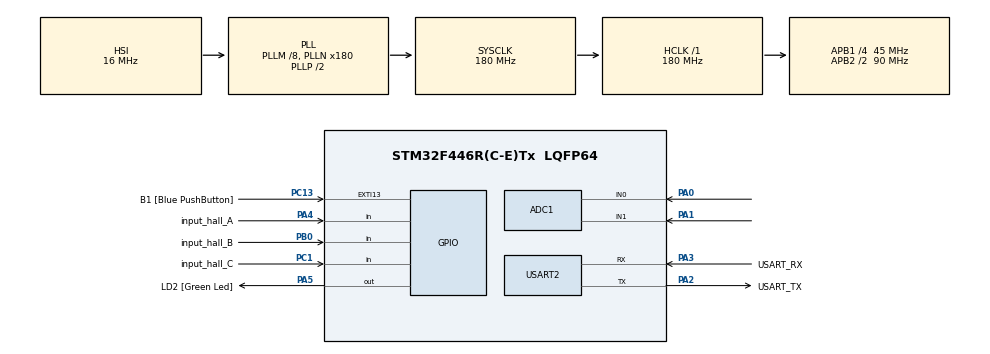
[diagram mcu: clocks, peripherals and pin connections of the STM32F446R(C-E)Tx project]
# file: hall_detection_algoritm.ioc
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ADC1.Channel-0\#ChannelRegularConversion=ADC_CHANNEL_0
ADC1.Channel-1\#ChannelRegularConversion=ADC_CHANNEL_1
ADC1.ContinuousConvMode=ENABLE
ADC1.DMAContinuousRequests=ENABLE
ADC1.EOCSelection=ADC_EOC_SEQ_CONV
ADC1.ExternalTrigConv=ADC_EXTERNALTRIGCONV_T8_TRGO
ADC1.InjNumberOfConversion=0
ADC1.NbrOfConversion=2
ADC1.NbrOfConversionFlag=1
ADC1.Rank-0\#ChannelRegularConversion=1
ADC1.Rank-1\#ChannelRegularConversion=2
ADC1.SamplingTime-0\#ChannelRegularConversion=ADC_SAMPLETIME_15CYCLES
ADC1.SamplingTime-1\#ChannelRegularConversion=ADC_SAMPLETIME_15CYCLES
ADC1.master=1
Dma.ADC1.0.Direction=DMA_PERIPH_TO_MEMORY
Dma.ADC1.0.FIFOMode=DMA_FIFOMODE_DISABLE
Dma.ADC1.0.Instance=DMA2_Stream0
Dma.ADC1.0.MemDataAlignment=DMA_MDATAALIGN_WORD
Dma.ADC1.0.MemInc=DMA_MINC_ENABLE
Dma.ADC1.0.Mode=DMA_CIRCULAR
Dma.ADC1.0.PeriphDataAlignment=DMA_PDATAALIGN_WORD
Dma.ADC1.0.PeriphInc=DMA_PINC_DISABLE
Dma.ADC1.0.Priority=DMA_PRIORITY_LOW
Dma.Request0=ADC1
Mcu.Family=STM32F4
Mcu.Name=STM32F446R(C-E)Tx
Mcu.Package=LQFP64
NVIC.DMA2_Stream0_IRQn=true\:0\:0\:false\:false\:true\:false\:true\:true
NVIC.PriorityGroup=NVIC_PRIORITYGROUP_0
NVIC.TIM8_UP_TIM13_IRQn=true\:0\:0\:false\:false\:true\:true\:true\:true
PA0-WKUP.Signal=ADCx_IN0
PA1.Signal=ADCx_IN1
PA13.GPIO_Label=TMS
PA13.Mode=Serial_Wire
PA13.Signal=SYS_JTMS-SWDIO
PA14.GPIO_Label=TCK
PA14.Mode=Serial_Wire
PA14.Signal=SYS_JTCK-SWCLK
PA2.GPIO_Label=USART_TX
PA2.Mode=Asynchronous
PA2.Signal=USART2_TX
PA3.GPIO_Label=USART_RX
PA3.Mode=Asynchronous
PA3.Signal=USART2_RX
PA4.GPIO_Label=input_hall_A
PA4.Signal=GPIO_Input
PA5.GPIO_Label=LD2 [Green Led]
PA5.Signal=GPIO_Output
PB0.GPIO_Label=input_hall_B
PB0.Signal=GPIO_Input
PC1.GPIO_Label=input_hall_C
PC1.Signal=GPIO_Input
PC13.GPIO_Label=B1 [Blue PushButton]
PC13.GPIO_ModeDefaultEXTI=GPIO_MODE_IT_FALLING
PC13.Signal=GPXTI13
ProjectManager.HeapSize=0x200
ProjectManager.StackSize=0x400
ProjectManager.TargetToolchain=STM32CubeIDE
RCC.AHBFreq_Value=180000000
RCC.APB1CLKDivider=RCC_HCLK_DIV4
RCC.APB1Freq_Value=45000000
RCC.APB1TimFreq_Value=90000000
RCC.APB2CLKDivider=RCC_HCLK_DIV2
RCC.APB2Freq_Value=90000000
RCC.APB2TimFreq_Value=180000000
RCC.CortexFreq_Value=180000000
RCC.FLatency-AdvancedSettings=FLASH_LATENCY_5
RCC.HCLKFreq_Value=180000000
RCC.HSE_VALUE=8000000
RCC.HSI_VALUE=16000000
RCC.LSE_VALUE=32768
RCC.PLLM=8
RCC.PLLN=180
RCC.SYSCLKFreq_VALUE=180000000
RCC.SYSCLKSource=RCC_SYSCLKSOURCE_PLLCLK
RCC.USBFreq_Value=180000000
RCC.VCOOutputFreq_Value=360000000
SH.ADCx_IN0.0=ADC1_IN0,IN0
SH.ADCx_IN1.0=ADC1_IN1,IN1
TIM8.Period=50-1
TIM8.Prescaler=180-1
TIM8.TIM_MasterOutputTrigger=TIM_TRGO_UPDATE
USART2.VirtualMode=VM_ASYNC
VP_TIM8_VS_ClockSourceINT.Mode=Internal
board=NUCLEO-F446RE

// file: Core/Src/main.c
/* USER CODE BEGIN Header */
/**
  ******************************************************************************
  * @file           : main.c
  * @brief          : Main program body
  ******************************************************************************
  * @attention
  *
  * Copyright (c) 2024 STMicroelectronics.
  * All rights reserved.
  *
  * This software is licensed under terms that can be found in the LICENSE file
  * in the root directory of this software component.
  * If no LICENSE file comes with this software, it is provided AS-IS.
  *
  ******************************************************************************
  */
/* USER CODE END Header */
#include "main.h"
#include "adc.h"
#include "dma.h"
#include "tim.h"
#include "usart.h"
#include "gpio.h"

/* USER CODE BEGIN Includes */
#include "hall_detection.h"
/* USER CODE END Includes */

/* USER CODE BEGIN PV */
#define numberofADCchannels 2
uint32_t ADCreadings[numberofADCchannels];

hall_pin_info H1={input_hall_A_GPIO_Port,input_hall_A_Pin,hall_direct,GPIO_PIN_RESET};
hall_pin_info H2={input_hall_B_GPIO_Port,input_hall_B_Pin,hall_direct,GPIO_PIN_RESET};
hall_pin_info H3={input_hall_C_GPIO_Port,input_hall_C_Pin,hall_direct,GPIO_PIN_RESET};

float translated_to_float_current0=0;
float translated_to_float_current1=0;

/* USER CODE END PV */

void SystemClock_Config(void);

int main(void)
{

  /* MCU Configuration--------------------------------------------------------*/

  /* Reset of all peripherals, Initializes the Flash interface and the Systick. */
  HAL_Init();

  /* Configure the system clock */
  SystemClock_Config();

  /* Initialize all configured peripherals */
  MX_GPIO_Init();
  MX_DMA_Init();
  MX_ADC1_Init();
  MX_USART2_UART_Init();
  MX_TIM8_Init();
  /* USER CODE BEGIN 2 */
 HAL_ADC_Start_DMA(&hadc1, ADCreadings, numberofADCchannels);
 HAL_TIM_Base_Start_IT(&htim8);
  /* USER CODE END 2 */

  /* Infinite loop */
  /* USER CODE BEGIN WHILE */
 Hall_start_detection();
  while (1)
  {
	  if(Hall_is_detection_finished()){//when finished the detection, just blink a green led LD2
		  HAL_Delay(70);
		  HAL_GPIO_TogglePin(LD2_GPIO_Port, LD2_Pin);
	  }

    /* USER CODE END WHILE */

  }
}

void SystemClock_Config(void)
{
  RCC_OscInitTypeDef RCC_OscInitStruct = {0};
  RCC_ClkInitTypeDef RCC_ClkInitStruct = {0};

  /** Configure the main internal regulator output voltage
  */
  __HAL_RCC_PWR_CLK_ENABLE();
  __HAL_PWR_VOLTAGESCALING_CONFIG(PWR_REGULATOR_VOLTAGE_SCALE1);

  /** Initializes the RCC Oscillators according to the specified parameters
  * in the RCC_OscInitTypeDef structure.
  */
  RCC_OscInitStruct.OscillatorType = RCC_OSCILLATORTYPE_HSI;
  RCC_OscInitStruct.HSIState = RCC_HSI_ON;
  RCC_OscInitStruct.HSICalibrationValue = RCC_HSICALIBRATION_DEFAULT;
  RCC_OscInitStruct.PLL.PLLState = RCC_PLL_ON;
  RCC_OscInitStruct.PLL.PLLSource = RCC_PLLSOURCE_HSI;
  RCC_OscInitStruct.PLL.PLLM = 8;
  RCC_OscInitStruct.PLL.PLLN = 180;
  RCC_OscInitStruct.PLL.PLLP = RCC_PLLP_DIV2;
  RCC_OscInitStruct.PLL.PLLQ = 2;
  RCC_OscInitStruct.PLL.PLLR = 2;
  if (HAL_RCC_OscConfig(&RCC_OscInitStruct) != HAL_OK)
  {
    Error_Handler();
  }

  /** Activate the Over-Drive mode
  */
  if (HAL_PWREx_EnableOverDrive() != HAL_OK)
  {
    Error_Handler();
  }

  /** Initializes the CPU, AHB and APB buses clocks
  */
  RCC_ClkInitStruct.ClockType = RCC_CLOCKTYPE_HCLK|RCC_CLOCKTYPE_SYSCLK
                              |RCC_CLOCKTYPE_PCLK1|RCC_CLOCKTYPE_PCLK2;
  RCC_ClkInitStruct.SYSCLKSource = RCC_SYSCLKSOURCE_PLLCLK;
  RCC_ClkInitStruct.AHBCLKDivider = RCC_SYSCLK_DIV1;
  RCC_ClkInitStruct.APB1CLKDivider = RCC_HCLK_DIV4;
  RCC_ClkInitStruct.APB2CLKDivider = RCC_HCLK_DIV2;

  if (HAL_RCC_ClockConfig(&RCC_ClkInitStruct, FLASH_LATENCY_5) != HAL_OK)
  {
    Error_Handler();
  }
}

void Error_Handler(void)
{
  __disable_irq();
  while (1)
  {
  }
}
